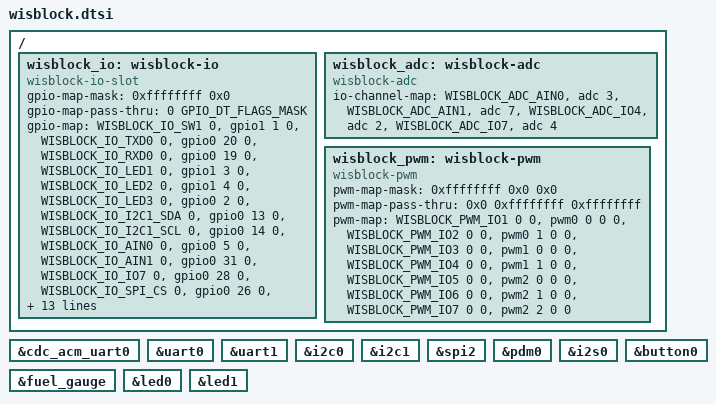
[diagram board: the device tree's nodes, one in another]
/*
 * SPDX-License-Identifier: Apache-2.0
 * Copyright (c) 2026 RAKwireless Technology Limited
 */

#include <zephyr/dt-bindings/gpio/wisblock-io-slot.h>
#include <zephyr/dt-bindings/adc/wisblock-adc.h>
#include <zephyr/dt-bindings/pwm/wisblock-pwm.h>

/ {
	wisblock_io: wisblock-io {
		compatible = "wisblock-io-slot";
		#gpio-cells = <2>;
		gpio-map-mask = <0xffffffff 0x0>;
		gpio-map-pass-thru = <0 GPIO_DT_FLAGS_MASK>;
		gpio-map =
			<WISBLOCK_IO_SW1	0	&gpio1	1	0>,
			<WISBLOCK_IO_TXD0	0	&gpio0	20	0>,
			<WISBLOCK_IO_RXD0	0	&gpio0	19	0>,
			<WISBLOCK_IO_LED1	0	&gpio1	3	0>,
			<WISBLOCK_IO_LED2	0	&gpio1	4	0>,
			<WISBLOCK_IO_LED3	0	&gpio0	2	0>,
			<WISBLOCK_IO_I2C1_SDA	0	&gpio0	13	0>,
			<WISBLOCK_IO_I2C1_SCL	0	&gpio0	14	0>,
			<WISBLOCK_IO_AIN0	0	&gpio0	5	0>,
			<WISBLOCK_IO_AIN1	0	&gpio0	31	0>,
			<WISBLOCK_IO_IO7	0	&gpio0	28	0>,
			<WISBLOCK_IO_SPI_CS	0	&gpio0	26	0>,
			<WISBLOCK_IO_SPI_CLK	0	&gpio0	3	0>,
			<WISBLOCK_IO_SPI_MISO	0	&gpio0	29	0>,
			<WISBLOCK_IO_SPI_MOSI	0	&gpio0	30	0>,
			<WISBLOCK_IO_IO1	0	&gpio0	17	0>,
			<WISBLOCK_IO_IO2	0	&gpio1	2	0>,
			<WISBLOCK_IO_IO3	0	&gpio0	21	0>,
			<WISBLOCK_IO_IO4	0	&gpio0	4	0>,
			<WISBLOCK_IO_TXD1	0	&gpio0	16	0>,
			<WISBLOCK_IO_RXD1	0	&gpio0	15	0>,
			<WISBLOCK_IO_I2C2_SDA	0	&gpio0	24	0>,
			<WISBLOCK_IO_I2C2_SCL	0	&gpio0	25	0>,
			<WISBLOCK_IO_IO5	0	&gpio0	9	0>,
			<WISBLOCK_IO_IO6	0	&gpio0	10	0>;
	};

	wisblock_adc: wisblock-adc {
		compatible = "wisblock-adc";
		#io-channel-cells = <1>;
		io-channel-map =
			<WISBLOCK_ADC_AIN0	&adc	3>,
			<WISBLOCK_ADC_AIN1	&adc	7>,
			<WISBLOCK_ADC_IO4	&adc	2>,
			<WISBLOCK_ADC_IO7	&adc	4>;
	};

	wisblock_pwm: wisblock-pwm {
		compatible = "wisblock-pwm";
		#pwm-cells = <3>;
		pwm-map-mask = <0xffffffff 0x0 0x0>;
		pwm-map-pass-thru = <0x0 0xffffffff 0xffffffff>;

		pwm-map =
			<WISBLOCK_PWM_IO1	0	0	&pwm0	0	0	0>,
			<WISBLOCK_PWM_IO2	0	0	&pwm0	1	0	0>,
			<WISBLOCK_PWM_IO3	0	0	&pwm1	0	0	0>,
			<WISBLOCK_PWM_IO4	0	0	&pwm1	1	0	0>,
			<WISBLOCK_PWM_IO5	0	0	&pwm2	0	0	0>,
			<WISBLOCK_PWM_IO6	0	0	&pwm2	1	0	0>,
			<WISBLOCK_PWM_IO7	0	0	&pwm2	2	0	0>;
	};
};

wisblock_console: &cdc_acm_uart0 {};

wisblock_uart0: &uart0 {};
wisblock_uart1: &uart1 {};
wisblock_i2c1: &i2c0 {};
wisblock_i2c2: &i2c1 {};
wisblock_spi: &spi2 {};
wisblock_pdm: &pdm0 {};
wisblock_i2s: &i2s0 {};
wisblock_sw1: &button0 {};
wisblock_vbat: &fuel_gauge {};
wisblock_led1: &led0 {};
wisblock_led2: &led1 {};

#include <wisblock/wisblock_sensor_c.dtsi>
#include <wisblock/wisblock_sensor_d.dtsi>
